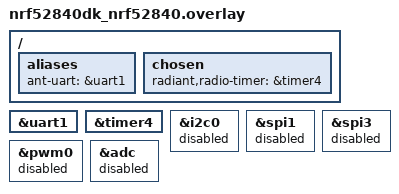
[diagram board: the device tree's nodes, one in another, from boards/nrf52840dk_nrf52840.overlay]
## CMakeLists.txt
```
# SPDX-License-Identifier: Apache-2.0

cmake_minimum_required(VERSION 3.20.0)

# The same ANT+ dongle as apps/dongle, plus Thread/Matter rebroadcast - see
# that app's own CMakeLists.txt header for why splitting the two apart,
# rather than a Kconfig variant of one, is the point.
#
# The sysbuild-cache reader and the RADIANT_BACKEND selection/assertion
# machinery are shared with every other RadiANT app (apps/dongle,
# apps/hrm_ble) rather than copy-pasted - see cmake/radiant_backend.cmake for
# the sysbuild mechanics this depends on. The ANT_RADIO axis (sdk_ant vs core
# vs stub) is the ANT-serial-dongle-specific half of the same idea, and lives
# in apps/common/ instead, for the reason that file's own header gives.
include("${CMAKE_CURRENT_SOURCE_DIR}/../../cmake/radiant_backend.cmake")
include("${CMAKE_CURRENT_SOURCE_DIR}/../common/ant_radio_backend.cmake")

# radiant is appended unconditionally, same reasoning as apps/dongle's own
# CMakeLists.txt: it is in this repository and always is, so CONFIG_RADIANT
# gates it rather than the module's presence gating anything.
#
# The default is "nrf", matching every other application in this repository.
# It used to be "null" on a cheap-compile-check argument; that argument is
# withdrawn, because the thing it protected - a bare `west build` that always
# configures - is worth less than never silently producing an inert radio.
#
# Note that "nrf" is the whole of the backend axis here. The P4 gate is NOT a
# RADIANT_BACKEND value: it is a separate Kconfig symbol,
# CONFIG_RADIANT_BACKEND_NRF_GATE_MPSL, which every fragment that turns on a
# second stack sets for itself (thread.conf, gate.conf, coex.conf, matter.conf).
# That is what satisfies RADIANT_BACKEND_NRF's `depends on !BT ||
# RADIANT_BACKEND_NRF_GATE_MPSL`, so this default is safe in the bare
# configuration - prj.conf alone enables neither BT nor OpenThread - and in
# every fragment combination the app actually ships.
#
# scripts/build_p4.ps1 still passes -DRADIANT_BACKEND=nrf explicitly and still
# reads .config back to prove it landed. Both remain right: an explicit flag
# and a read-back do not stop being worthwhile because the default now agrees
# with them.
radiant_select_backend("${CMAKE_CURRENT_SOURCE_DIR}/../../radiant" "nrf" RADIANT_BACKEND_CONF)
ant_select_radio("${CMAKE_CURRENT_SOURCE_DIR}" "" "${RADIANT_BACKEND_CONF}" ANT_RADIO_CONF)

# Write only on a change - see apps/dongle/CMakeLists.txt for the full
# rationale (CMAKE_CONFIGURE_DEPENDS churn on every configure otherwise).
set(ANT_RADIO_CONF_FILE "${CMAKE_CURRENT_BINARY_DIR}/ant_radio_backend.conf")
set(ANT_RADIO_CONF_EXISTING "")
if(EXISTS "${ANT_RADIO_CONF_FILE}")
  file(READ "${ANT_RADIO_CONF_FILE}" ANT_RADIO_CONF_EXISTING)
endif()
if(NOT ANT_RADIO_CONF_EXISTING STREQUAL ANT_RADIO_CONF)
  file(WRITE "${ANT_RADIO_CONF_FILE}" "# Generated by CMakeLists.txt from -DANT_RADIO. Do not edit; do not commit.\n${ANT_RADIO_CONF}")
endif()

find_package(Zephyr REQUIRED HINTS $ENV{ZEPHYR_BASE})
project(radiant_dongle_thread)

# See apps/common/ant_radio_backend.cmake's ant_assert_radio() - only
# relevant when ANT_RADIO chose radiant in the first place.
ant_assert_radio("radiant_dongle_thread")

target_sources(app PRIVATE src/main.c)

# ── apps/common: the antr_* seam, the serial bridge and its transports ─────
#
# One source list, added fresh into this application's own image - see that
# file's own header for why it is include()d rather than add_subdirectory()'d.
# CONFIG_ANT_DONGLE_TRANSPORT_* (set by the choice in Kconfig) and
# CONFIG_ANT_DONGLE_RADIO_*/CONFIG_RADIANT_ANTR_API (set above by
# ant_select_radio() and by apps/common/Kconfig.antr_api's default) together
# decide what actually compiles from it into this image.
include("${CMAKE_CURRENT_SOURCE_DIR}/../common/sources.cmake")

# ── The RadiANT bridge: the sample bus and everything on it ─────────────────
#
# docs/radiant-bridge.md sections 3-6 and 9. THE MODULE OWNS radiant/src/bridge/
# AND radiant/src/profiles/: CONFIG_RADIANT_BRIDGE (radiant/Kconfig) compiles
# both into the radiant library, adds both include paths and adds the linker
# fragment. This application lists none of those files - listing them as well
# is a duplicate-definition link failure, which is what 1d0d821 caused here.
# Only this application's own half, under src/, is added below.
#
# What decides which module code is LINKED is therefore the call graph, not a
# source list. The files with no sink (the bus, the binding table, the
# adapters, naming, the owed list, the self-channel policy, every profile
# codec) are dropped by the linker unless something here calls them. The three
# files that register a sink cannot be left to the linker, because a
# RADIANT_SINK_DEFINE() is kept whether or not anything calls into its file:
# radiant_rules.c and radiant_liveness.c follow CONFIG_RADIANT_BRIDGE_RULES and
# CONFIG_RADIANT_BRIDGE_LIVENESS, which this application's Kconfig defaults on,
# and radiant_matter.c follows CONFIG_RADIANT_BRIDGE_MATTER_MAP, which
# CONFIG_ANT_DONGLE_MATTER_MAP selects. Liveness lands with the bus, not after
# a sink: RADIANT_SAMPLE_STALE was defined and honoured since P6 with nothing
# producing it, and a sink written against a bus that never marks anything
# stale grows that assumption into itself.
#
# THE LINKER FRAGMENT IS NOT OPTIONAL, even though it is now the module's line
# rather than this file's. RADIANT_SINK_DEFINE() (radiant_bridge.h) uses
# STRUCT_SECTION_ITERABLE, which emits each sink into a section named after the
# struct type. Emitting into a section and having that section PLACED - with
# the _radiant_sink_list_start / _end symbols STRUCT_SECTION_FOREACH() walks
# between - are two different things, and radiant_sink has no in-tree linker
# fragment of its own the way shell commands and bt_conn_cb do. Without it the
# best case is an undefined reference at the final link; the worse case is that
# it links and STRUCT_SECTION_FOREACH() silently iterates ZERO sinks, which is
# not a compile error, not a link error, and looks from the console exactly
# like "no sensors in range". src/bridge_pump.c logs the count at boot for that
# reason: "bridge: 0 sinks" is the failure announcing itself.
#
# radiant_rd_adapter.c is compiled by the module and deliberately NOT CALLED
# here, so it is not linked. It is tested (radiant/tests builds it), but the
# running-dynamics adapter has no bench evidence behind it yet, and linking it
# would make an untested path look like a shipped one.
#
# radiant_matter.c is on ITS OWN Kconfig symbol (CONFIG_ANT_DONGLE_MATTER_MAP),
# not on CONFIG_CHIP. It contains no CHIP call at all: it is the section 8.1
# field-type -> cluster map plus a __weak radiant_matter_attr_write(), and it
# compiles identically with or without connectedhomeip in the workspace. Tying
# it to CONFIG_CHIP would have made a pure-C lookup table unbuildable on the
# nRF52840 Matterless escape hatch (docs/radiant-bridge.md section 11) for no
# reason, and Kconfig says why it defaults to n even here.
#
# The Matter plan's packages A, B and C - three more adapters and the page
# codecs behind them - follow CONFIG_ANT_DONGLE_PROFILES_EXTRA, which gates the
# CALLS in src/rx_tap.c and src/self_channels.c. NOT CONFIG_RADIANT_BRIDGE, AND
# THAT IS THE WHOLE POINT OF THE SYMBOL: docs/matter-bringup.md measured
# bridge.conf gaining 2 564 B of flash, 1 472 B of RAM and 22 defined symbols
# plus a changed radio schedule when they were not separate. See that symbol's
# help in Kconfig. Two things about what it links are load-bearing:
#
# 1. THE COMMON-PAGE PAIR IS NOT OPTIONAL AND IS NOT PER-PROFILE.
#    ANT+ Common Data Pages Rev 3.1 Table 4-1 keys pages 0x40-0x5D on the
#    channel's TRANSMISSION TYPE, not on the device type, so the common
#    decoder runs on every bound channel alongside whichever profile
#    adapter owns it - see src/rx_tap.c. Omitting it does not disable a
#    feature, it makes every weather-reporting sensor silent.
#
# 2. profile_power_decode.c, NOT profile_power.c. The latter is the
#    MASTER - page rotation, the ANT+ compat layer, RadiANT beacon
#    insertion - so it calls profile_sched.c and profile_compat.c, and
#    profile_compat.c reaches radiant_sec. Both are compiled by the module;
#    calling profile_power.c from here to obtain one decoder would pull the
#    entire transmit-side chain into an image whose whole job is to listen,
#    and would let a linker decision nobody reviewed make a receive-only
#    dongle capable of transmitting. See that file's header; the split exists
#    for this reason. `nm` on the ELF is the check: no profile_power_*
#    master symbol may appear.
if(CONFIG_RADIANT_BRIDGE)
  # The application half: the drain pump and the 1 Hz liveness clock.
  target_sources(app PRIVATE "${CMAKE_CURRENT_SOURCE_DIR}/src/bridge_pump.c")
  target_include_directories(app PRIVATE "${CMAKE_CURRENT_SOURCE_DIR}/src")
endif()

# ── The CHIP stack and the vendored Matter bridge core (package E3/E7) ──────
#
# EVERYTHING MATTER IS INSIDE THIS ONE `if`, and that is a requirement rather
# than tidiness. gate.conf, thread.conf, thread_sed.conf, coex.conf and
# bridge.conf carry the P3/P4 coexistence baselines in
# docs/radiant-bridge.md section 7.4, and those numbers describe the images
# they were taken on. CONFIG_CHIP is n in all five (matter_sysbuild.conf is
# named on the command line, never picked up automatically - see that file's
# header), so not one line below runs for them and their images are unchanged
# by construction rather than by care.
#
# WHY IT IS HERE AND NOT BEFORE find_package(Zephyr). The preamble at the top
# of this file - radiant_backend.cmake and ant_radio_backend.cmake - only
# generates .conf fragments and appends module paths; it creates no target and
# reads no Kconfig. Everything below needs both `app` to exist and
# CONFIG_* to be readable, so it belongs after project(). The two NCS
# applications that do this - nrf/applications/matter_bridge/CMakeLists.txt
# and nrf/samples/matter/template/CMakeLists.txt - are laid out exactly this
# way and this block follows them line for line.
#
# THE APPLICATION DOES NOT BECOME C++. Only the .cpp files listed below are,
# and enable-gnu-std.cmake only appends C++ flags. src/main.c and everything
# under apps/common stay C, and CONFIG_STD_CPP17 (matter.conf, with a long
# note on why it is not optional) applies to the C++ half alone.
if(CONFIG_CHIP)
  # -std=gnu++17 rather than -std=c++17 for the CHIP sources. Without it,
  # connectedhomeip does not compile - see matter.conf's CONFIG_STD_CPP17 note
  # for the 40-line error that looks like a broken toolchain and is not.
  include(${ZEPHYR_CONNECTEDHOMEIP_MODULE_DIR}/config/nrfconnect/app/enable-gnu-std.cmake)

  # NCS's Matter sample-common sources: board/led_widget, the task executor,
  # matter_init, the event handler and the code-driven cluster registry (plus
  # its cluster_init.ld linker fragment, which this file therefore does NOT
  # repeat). Every Matter sample and application in NCS includes this and the
  # bridge core expects the persistent-storage and binding pieces of it to be
  # present.
  #
  # board.cpp IS COMPILED AND DOES NOT DRIVE ANY LED HERE. Both its LED paths
  # are inside `#ifdef CONFIG_DK_LIBRARY` and this arm does not enable
  # DK_LIBRARY, so the collision matter.conf's CONFIG_NCS_SAMPLE_MATTER_LEDS=n
  # was written to prevent (NCS driving DK LEDs 0-3 against
  # apps/common/ant_heartbeat_led.c's led0) cannot happen twice over. The =n line
  # stays because it states the decision; this comment states the measurement.
  include(${ZEPHYR_NRF_MODULE_DIR}/samples/matter/common/cmake/source_common.cmake)

  # ncs_configure_data_model() and ncs_get_zap_parent_dir(), both of which read
  # CONFIG_NCS_SAMPLE_MATTER_ZAP_FILE_PATH - set in matter.conf to this
  # application's own src/matter/default_zap/bridge.zap.
  include(${ZEPHYR_NRF_MODULE_DIR}/samples/matter/common/cmake/data_model.cmake)
  include(${ZEPHYR_NRF_MODULE_DIR}/samples/matter/common/cmake/zap_helpers.cmake)
  ncs_get_zap_parent_dir(ZAP_PARENT_DIR)

  target_include_directories(app PRIVATE
    "${CMAKE_CURRENT_SOURCE_DIR}/src/matter"
    "${CMAKE_CURRENT_SOURCE_DIR}/src/matter/core"
    "${CMAKE_CURRENT_SOURCE_DIR}/src/matter/core/util"
    # zap-generated/ lands on the include path through its PARENT directory,
    # because the generated sources include it as <zap-generated/...>. This is
    # the line that makes the committed ZAP output the thing the build reads;
    # ncs_configure_data_model() adds the same directory to the separate
    # matter-data-model target.
    ${ZAP_PARENT_DIR}
  )

  target_sources(app PRIVATE
    # The vendored bridge core. src/matter/README.md records the source path,
    # the NCS version and everything that was left behind - the whole BLE
    # central provider first among it.
    "${CMAKE_CURRENT_SOURCE_DIR}/src/matter/core/bridge_manager.cpp"
    "${CMAKE_CURRENT_SOURCE_DIR}/src/matter/core/matter_bridged_device.cpp"
    "${CMAKE_CURRENT_SOURCE_DIR}/src/matter/core/bridge_storage_manager.cpp"
    "${CMAKE_CURRENT_SOURCE_DIR}/src/matter/core/bridged_device_data_provider.cpp"
    # NOT vendored, referenced in place, exactly as matter_bridge does:
    # BridgeManager::Init() calls Nrf::Matter::BindingHandler::Init() and
    # BridgeManager::HandleCommand() builds its BindingData. It is NCS's file
    # and there is no reason for this repository to own a copy.
    "${ZEPHYR_NRF_MODULE_DIR}/samples/matter/common/src/binding/binding_handler.cpp"
  )

  # ── Packages E4, E5 and E6: the ANT+ half, the device types and main() ────
  #
  # Everything here is THIS repository's, not vendored - src/matter/README.md's
  # provenance table covers core/ and default_zap/ and nothing below.
  #
  # ONE OF THESE FIVE FILES IS C, AND THAT IS DELIBERATE.
  # ant/ant_matter_sink.c carries the RADIANT_SINK_DEFINE() that gives the glue
  # a binding_changed callback and a view of RADIANT_SAMPLE_STALE. That macro is
  # STRUCT_SECTION_ITERABLE plus a designated initialiser; designated
  # initialisers are only a GNU extension in C++17 and the iterable-section
  # machinery wants an unmangled symbol in a section named after the struct.
  # Both happen to work under -std=gnu++17 and neither is guaranteed, so the
  # nine lines that need them are C. See that file's header.
  #
  # NESTED INSIDE CONFIG_RADIANT_BRIDGE, exactly like the trap-15 assertions
  # below and for the same mechanical reason: ant_bridge.cpp includes
  # radiant_matter.h and ant_matter_sink.c includes radiant_bridge.h, and
  # radiant/src/bridge only reaches the include path when the module sees
  # CONFIG_RADIANT_BRIDGE (src/bridge_app.h likewise comes from the block
  # further up). It is not a second opinion about
  # whether Matter is wanted - matter.conf sets both symbols and CONFIG_CHIP
  # without the sample bus would be a bridge with nothing to bridge.
  #
  # Note what is NOT the guard: CONFIG_ANT_DONGLE_MATTER, which is what main.c
  # tests. That symbol `depends on CHIP` and has no default, so a CHIP build
  # that left it unset compiles these files, links them, and finds nothing
  # calls ant_matter_start() - a dead sink and a --gc-sections discard. The
  # other order (guarding the sources and not the call) is the one that fails,
  # at link.
  if(CONFIG_RADIANT_BRIDGE)
    target_sources(app PRIVATE
      "${CMAKE_CURRENT_SOURCE_DIR}/src/matter/ant/ant_bridge.cpp"
      "${CMAKE_CURRENT_SOURCE_DIR}/src/matter/ant/ant_matter_sink.c"
      "${CMAKE_CURRENT_SOURCE_DIR}/src/matter/bridged_device_types/occupancy_sensor.cpp"
      "${CMAKE_CURRENT_SOURCE_DIR}/src/matter/bridged_device_types/measurement_sensor.cpp"
      # E6. It also carries the one LOG_MODULE_REGISTER(app) this image has:
      # every vendored core file and every NCS sample-common source does
      # LOG_MODULE_DECLARE(app), and upstream registers it in the main.cpp that
      # E3 deliberately did not vendor.
      "${CMAKE_CURRENT_SOURCE_DIR}/src/matter/matter_app.cpp"
      # Trap 15's static_assert. Same include-path reason as the four above;
      # not a statement that the assertion is optional.
      "${CMAKE_CURRENT_SOURCE_DIR}/src/matter/bridge_core_asserts.cpp")
  endif()

  # Compiles src/matter/default_zap/zap-generated/ into the matter-data-model
  # target, with BYPASS_IDL - so chip_zapgen never runs and the COMMITTED
  # directory is what the image contains. See src/matter/README.md; this is
  # trap 13 and it is the reason .zap, .matter and zap-generated/ were copied
  # across together and unmodified.
  ncs_configure_data_model()
endif()

# ADR 0018 Phase 1 bench BLE load (ble_load.conf). Never in a shipping image.
target_sources_ifdef(CONFIG_ANT_DONGLE_BLE_LOAD app PRIVATE
  "${CMAKE_CURRENT_SOURCE_DIR}/src/ble_load.c")

target_sources_ifdef(CONFIG_ANT_DONGLE_RX_TAP app PRIVATE
  "${CMAKE_CURRENT_SOURCE_DIR}/src/rx_tap.c")

# CONFIG_ANT_DONGLE_SELF_CHANNELS is an int, so target_sources_ifdef() (which
# tests for truthiness) would fire on 0 as well - Kconfig writes
# CONFIG_ANT_DONGLE_SELF_CHANNELS=0 rather than leaving it unset for an int
# symbol. Compare explicitly.
if(CONFIG_ANT_DONGLE_SELF_CHANNELS GREATER 0)
  # Its decisions are pure functions in radiant/src/bridge/radiant_self_policy.c,
  # where radiant/tests can reach them (this app's sources it cannot); the
  # module compiles that file under CONFIG_RADIANT_BRIDGE. See that header.
  target_sources(app PRIVATE "${CMAKE_CURRENT_SOURCE_DIR}/src/self_channels.c")
  # try_bind() once fell off its end and the built code returned a stale
  # register, rotating a just-bound channel away (review 2026-10-31, C3-1).
  # Per file, not app-wide: app-wide would reach vendored and zap C++.
  set_source_files_properties("${CMAKE_CURRENT_SOURCE_DIR}/src/self_channels.c"
    PROPERTIES COMPILE_OPTIONS "-Werror=return-type")
endif()

target_sources_ifdef(CONFIG_ANT_DONGLE_MQTT_SINK app PRIVATE
  "${CMAKE_CURRENT_SOURCE_DIR}/src/mqtt_sink.c")

# ── The hostless node's identity (compat-C6) ────────────────────────────────
#
# Same wiring as apps/dongle's own CMakeLists.txt - see that file's comment
# for the full rationale. Off by default here too: this application's epoch
# authority is still the PC behind it, same as the plain dongle.
if(CONFIG_RADIANT_NODE_IDENT)
  target_sources(app PRIVATE ../../radiant/src/node/node_ident.c)
  target_include_directories(app PRIVATE ../../radiant/src/node)
endif()
if(CONFIG_RADIANT_NODE_NVM_SETTINGS)
  target_sources(app PRIVATE ../../radiant/src/node/node_nvm_settings.c)
endif()
```

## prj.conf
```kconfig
# Board-specific settings live in boards/<board>.conf. The Thread/coexistence
# stack itself is opt-in through EXTRA_CONF_FILE (gate.conf, coex.conf,
# thread.conf, thread_sed.conf) rather than baked in here, so a plain
# `west build apps/dongle_thread` with no extra fragment is an ordinary
# ANT+-only dongle image - see scripts/build_p4.ps1 for how the bench arms
# turn the second stack on.

# The ANT stack settings - CONFIG_ANT, CONFIG_ANT_EVALUATION_KEY,
# CONFIG_ANT_TOTAL_CHANNELS_ALLOCATED and CONFIG_ANT_BURST_QUEUE_SIZE - are
# written by CMakeLists.txt into a generated fragment alongside the
# CONFIG_ANT_DONGLE_RADIO_* symbol naming the backend, same as apps/dongle.
# They name symbols that exist only when sdk-ant's Kconfig has been sourced,
# and it is CMake that decides whether that happens.

# Logging via RTT by default; a board's own boards/<board>.conf overrides
# this to a UART VCOM where RTT needs tooling the bench does not carry.
CONFIG_LOG=y
CONFIG_LOG_MODE_DEFERRED=y
CONFIG_USE_SEGGER_RTT=y
CONFIG_LOG_BACKEND_RTT=y
CONFIG_LOG_BACKEND_UART=n
CONFIG_SEGGER_RTT_MODE_NO_BLOCK_SKIP=y
CONFIG_LOG_BACKEND_RTT_MODE_DROP=y

# Heap and threads
CONFIG_HEAP_MEM_POOL_SIZE=4096
CONFIG_MAIN_STACK_SIZE=2048
CONFIG_RESET_ON_FATAL_ERROR=y
CONFIG_REBOOT=y

CONFIG_CONSOLE=n
CONFIG_UART_CONSOLE=n
CONFIG_SHELL=n

CONFIG_ANT_DONGLE_BCD_DEVICE=0x0100

# The boot sequence itself is apps/common/ant_dongle_main.c, shared with
# apps/dongle. This is the one line of it that differs between the two
# applications; src/main.c's override of the weak post-radio hook is the other
# difference, and it is code rather than configuration.
CONFIG_ANT_DONGLE_MAIN_BANNER="ANT+ USB Dongle + Thread"

# Ring buffer for USB RX data
CONFIG_RING_BUFFER=y

# GPIO for onboard LED activity signal
CONFIG_GPIO=y

# The boot reset cause - see apps/dongle/prj.conf.
CONFIG_HWINFO=y
```

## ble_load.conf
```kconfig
# SPDX-License-Identifier: Apache-2.0
#
# Bench only (ADR 0018 Phase 1): coex.conf plus an advertiser that actually
# advertises (src/ble_load.c), so MPSL has a second stack with events on the
# schedule. Use instead of gate.conf:
#
#   "-DEXTRA_CONF_FILE=coex.conf;ble_load.conf;phase_diag.conf;d2_stats.conf"
#
# Never in a shipping image.
CONFIG_ANT_DONGLE_BLE_LOAD=y
CONFIG_ANT_DONGLE_BLE_LOAD_INTERVAL_MS=1000
```

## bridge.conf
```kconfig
# SPDX-License-Identifier: Apache-2.0
#
# The RadiANT bridge, as a build: ANT+ in, MQTT over Thread out.
#
#   west ... -- "-DANT_RADIO=core" "-DRADIANT_BACKEND=nrf" \
#               "-DEXTRA_CONF_FILE=thread.conf;bridge.conf"
#
# ---------------------------------------------------------------------------
# THIS IS A SEPARATE FRAGMENT ON PURPOSE. DO NOT FOLD IT INTO thread.conf.
# ---------------------------------------------------------------------------
#
# CONFIG_NET_TCP is deliberately absent from thread.conf, which says why in its
# own words: flash the gate image does not need, plus air time the gate would
# then have to account for. docs/radiant-bridge.md section 7.4's coexistence
# numbers - the ones recorded in 7.4.2 as a PASS - were taken on a TCP-FREE
# IMAGE. An image with a TCP stack, a broker connection and a keepalive thread
# in it is a different image, and quoting 7.4's numbers against it would be
# quoting a measurement of something else.
#
# So: the gate arms (gate.conf, thread.conf, thread_sed.conf) stay TCP-free,
# this fragment layers on top of thread.conf for a bridge build, and a
# coexistence figure taken with this fragment on is its own measurement with
# its own row.

# ── The bus ────────────────────────────────────────────────────────────────
#
# Note what this brings with it: the linker fragment
# radiant/src/bridge/radiant_bridge_sections.ld, through
# zephyr_linker_sources() in radiant/CMakeLists.txt, along with the module's
# bridge and profile sources. Watch for "bridge: N sinks" in the
# boot log; N of 0 means every sink in the image is dead code and nothing
# downstream can work.
CONFIG_RADIANT_BRIDGE=y
CONFIG_ANT_DONGLE_RX_TAP=y

# ── Self-driving channels and the pairing window ───────────────────────────
#
# Two channels, taken from the top of the ANT allocation downward so a host
# library allocating from 0 upward collides last. Acquiring is not binding: a
# press of sw0 opens a 60 s window, and outside it an unbound device's
# broadcasts are dropped (section 10.1 rule 1, and section 5 - binding is
# explicit opt-in, never promiscuous).
CONFIG_ANT_DONGLE_SELF_CHANNELS=2
CONFIG_ANT_DONGLE_PAIRING_WINDOW_S=60

# ── MQTT ───────────────────────────────────────────────────────────────────
#
# TCP is the whole reason this fragment exists. NET_SOCKETS, NET_IPV6 and the
# OpenThread L2 come from thread.conf, which this is layered on top of.
CONFIG_NET_TCP=y
CONFIG_MQTT_LIB=y
CONFIG_MQTT_LIB_TLS=n

CONFIG_ANT_DONGLE_MQTT_SINK=y

# A PLACEHOLDER, and it is certainly not your broker. Numeric IPv6 only:
# section 9.0a's DNS-SD discovery is deferred (it rests on two things nobody
# has verified on real hardware), so there is no resolver call in this build
# and a hostname here is an error rather than an unimplemented feature.
CONFIG_ANT_DONGLE_MQTT_BROKER="fd11:22::1"
CONFIG_ANT_DONGLE_MQTT_PORT=1883
CONFIG_ANT_DONGLE_MQTT_BRIDGE_ID="radiant0"

# CONFIG_NET_CONFIG_NEED_IPV6 IS DELIBERATELY ABSENT HERE TOO, and the reason
# is thread.conf's, unchanged: it blocks net_config_init() until the interface
# has an IPv6 address, before main(), for up to 30 s - measured at 31.04 s on
# an unattached MTD on this bench, reproducible to the tenth, and read as a
# hung board by a human and by ant_verify.py in the same session.
#
# src/mqtt_sink.c connects on its FIRST PUBLISH and never at boot. A connect
# that fails is retried on the next sample rather than being fatal.
#
# ONE CORRECTION TO thread.conf's WORDING, FOUND BY READING THIS BUILD'S OWN
# .config RATHER THAN THE FRAGMENTS. thread.conf says NET_CONFIG_NEED_IPV6 is
# "deliberately absent"; it is absent from that FILE, but it defaults to y once
# CONFIG_NET_CONFIG_SETTINGS and CONFIG_NET_IPV6 are both on, and this build's
# generated .config reads CONFIG_NET_CONFIG_NEED_IPV6=y. What actually prevents
# the 31 s stall is the line beside it - CONFIG_NET_CONFIG_INIT_TIMEOUT=0,
# which makes the wait return immediately.
#
# So the timeout is restated HERE rather than inherited, because it is the line
# that is load-bearing and a fragment layered on top of a different base must
# not lose it. Verified in build/p2_bridge/dongle_thread/zephyr/.config:
# NEED_IPV6=y, INIT_TIMEOUT=0.
CONFIG_NET_CONFIG_INIT_TIMEOUT=0

# Buffers. The bridge adds a TCP connection, a 512 B MQTT tx buffer, a 256 B rx
# buffer and two threads to the OpenThread build's existing demand; thread.conf
# sizes the heap for OpenThread alone, so this raises it rather than discovering
# the shortfall as intermittent send failures that look like contention loss.
CONFIG_HEAP_MEM_POOL_SIZE=49152
CONFIG_NET_PKT_RX_COUNT=16
CONFIG_NET_PKT_TX_COUNT=16
CONFIG_NET_BUF_RX_COUNT=32
CONFIG_NET_BUF_TX_COUNT=32

# ── Reboot on a fatal error: the SHIPPING setting ──────────────────────────
#
# thread.conf sets this n, as a bench setting for the gate arms: a halted board
# keeps its fault dump on the console. This build is the one a user leaves
# running, and a bridge that halts on a transient fault publishes nothing until
# someone power-cycles it, where one that reboots is back within seconds. So
# this fragment overrides thread.conf here. It covers the MPSL assert too:
# radiant_radio_nrf_gate_mpsl.c's mpsl_assert_handle() reboots under this
# symbol and halts without it. Nothing survives the reboot - no crash record,
# since diag_flash_log.c cannot link beside this setting - so on the bench the
# dump on the console is all there is; build with thread.conf alone to get a
# board that stays halted on it.
CONFIG_RESET_ON_FATAL_ERROR=y
```

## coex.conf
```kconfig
# SPDX-License-Identifier: Apache-2.0
#
# The multiprotocol plan's P3 coexistence gate, as a build.
#
# SCOPE, SINCE THE LOAD GENERATOR WAS RETIRED: P3/P4 concluded and
# ble_coex_load.c was deleted with it, so this fragment no longer advertises
# anything. What it still buys is the build-time half - that CONFIG_BT=y beside
# the gate links, and that the backend does not fall to null (the second trap
# below). It is NOT a runtime coexistence measurement any more, and a CI row
# building it proves nothing about air behaviour. Restoring the adversarial
# advertiser means restoring ble_coex_load.c from git history.
#
#   west ... -- "-DANT_RADIO=core" "-DRADIANT_BACKEND=nrf" \
#               "-DEXTRA_CONF_FILE=coex.conf"
#
# -DANT_RADIO=core IS NOT OPTIONAL AND IS NOT THE DEFAULT. The root build
# defaults to the sdk-ant radio, which leaves CONFIG_RADIANT=n - and then
# every RADIANT_* line below is dropped with an "unsatisfied dependencies:
# RADIANT (=n)" warning. Leaving it out here fails loudly only by accident
# (sdk-ant then fails to link for the wrong float ABI); on a board where it
# links, it would silently measure the sdk-ant stack instead of this one.
#
# This is the CONTENDED half of an A/B. The other half is the same image without
# this fragment: gate on, no second stack. Read both or neither - the question
# the gate answers is a difference between two images, never a property of one.
#
# WHY EVERY LINE IS HERE, because three of the four are silent-fallback traps
# this project has now paid for more than once:
#
#   - CONFIG_BT=y ALONE IS NOT A SECOND STACK. It links the SoftDevice
#     Controller in and leaves it asleep, asking MPSL for no air whatsoever.
#     Measured, and it produced a sweep-rate ratio of exactly 1.000 between
#     "BLE off" and "BLE on" - a gate that cannot fail.
#   - CONFIG_BT=y also breaks the `!BT` half of RADIANT_BACKEND_NRF's
#     `depends on !BT || RADIANT_BACKEND_NRF_GATE_MPSL`, so without the
#     gate line below the whole radio backend silently becomes
#     RADIANT_BACKEND_NULL - an image that enumerates, answers the host,
#     and puts nothing on the air. That is not a bad measurement, it is a
#     measurement of nothing, and it reports EXIT=0.
#   - The gate itself is `select MPSL`, so nothing else needs turning on. It was
#     `depends on MPSL` once, which meant asking for the arbitrated build
#     without a second stack quietly compiled the DIRECT backend - i.e. the A of
#     this very A/B measured the wrong thing.
#
# ALWAYS CHECK THE GENERATED .config, NOT THE BUILD LOG. Every trap above ends
# in a warning among a hundred others and an exit code of 0:
#
#   Select-String build\<dir>\<app>\zephyr\.config `
#       -Pattern "^CONFIG_RADIANT_BACKEND_"
#
# EXEMPTION FROM THE W2 BLE POLICY (apps/hrm_ble/Kconfig,
# apps/treadmill/Kconfig): those two applications now redeclare
# BT_PERIPHERAL_PREF_MIN_INT/MAX_INT/LATENCY/TIMEOUT to 800/800/0/400 and
# fix le_param_req to enforce it, because THEY are the ANT+ side that needs
# BLE shaped down to 1 s. This file is the opposite instrument: it is the
# bench advertiser the gate is measured AGAINST, and its whole job is to be
# the adversarial neighbour those two applications defend against - at a
# deliberately-adversarial 100 ms advertising rate. Applying the 1 s policy
# here would tune the load down and understate every number the coexistence
# gate produces. Deliberately left off. (Moot while the load generator is
# retired - see SCOPE above - but the reasoning stands if it is restored.)

CONFIG_BT=y
CONFIG_BT_PERIPHERAL=y
CONFIG_BT_DEVICE_NAME="RadiANT Coex Load"

# Named rather than inherited. It is the default controller on a Nordic board,
# so this line changes nothing today - and it is the one fact that makes the
# plan's finding 1 true: the SoftDevice Controller is another MPSL user holding
# priority levels above anything an application timeslot request may ask for. A
# build that had silently fallen back to the Zephyr controller would be
# measuring a different arbitration, and every number would be optimistic.
#
# CONFIG_BT_CTLR is NOT a symbol to set - it is selected by the controller
# choice, and assigning it in v3.4.0 is a Kconfig warning that fails the build.
CONFIG_BT_LL_SOFTDEVICE=y

# The arbiter. See the second trap above: with CONFIG_BT=y and without this,
# the radio backend is silently the null one.
CONFIG_RADIANT_BACKEND_NRF_GATE_MPSL=y
# ADR 0018 (d2): one more for the gate's second session (RADIANT_GATE_MPSL_D2).
CONFIG_MPSL_TIMESLOT_SESSION_COUNT=2
```

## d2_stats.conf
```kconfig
# SPDX-License-Identifier: Apache-2.0
#
# Bench only: the MPSL gate's counters every 5 s on the log console (GATESTAT).
# Add beside gate.conf, thread.conf or coex.conf. Never in a shipping image.
CONFIG_RADIANT_GATE_MPSL_STATS_LOG=y
```

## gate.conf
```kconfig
# SPDX-License-Identifier: Apache-2.0
#
# The A of the coexistence A/B: the arbiter, with NO second stack.
#
#   west ... -- "-DANT_RADIO=core" "-DRADIANT_BACKEND=nrf" \
#               "-DEXTRA_CONF_FILE=gate.conf"
#
# The B is coex.conf, which is this plus a SoftDevice Controller that actually
# advertises. Read the two together; a number from either alone says nothing,
# because the question is what the other stack's demand costs us and that is a
# difference between two images.
#
# WHY THIS FILE EXISTS AT ALL, rather than "just leave coex.conf off". Turning
# on the gate is one line, and getting it wrong is silent both ways:
#
#   - RADIANT_BACKEND_NRF_GATE_MPSL was once `depends on MPSL` rather than
#     `select MPSL`, and nothing else in this tree enables MPSL. So asking for
#     the arbitrated build without a second stack - i.e. THIS measurement -
#     quietly compiled the DIRECT backend, and the A of the A/B measured the
#     thing the A/B was trying to isolate. It is `select` now; this fragment
#     names it anyway, so the intent survives another refactor of that line.
#   - A build with neither this nor coex.conf is the DIRECT backend, which is a
#     legitimate third measurement (the floor) and NOT the A. Three builds,
#     three fragments' worth of intent: direct = neither file, arbiter-only =
#     this file, contended = coex.conf.
#
# CHECK THE GENERATED .config, NOT THE BUILD LOG:
#
#   Select-String build\<dir>\<app>\zephyr\.config -Pattern "^CONFIG_RADIANT_BACKEND_"
#
# Expect BACKEND_NRF=y AND BACKEND_NRF_GATE_MPSL=y. BACKEND_NULL=y here is the
# failure that reports EXIT=0 and puts nothing on the air.

CONFIG_RADIANT_BACKEND_NRF_GATE_MPSL=y
# ADR 0018 (d2): one more for the gate's second session (RADIANT_GATE_MPSL_D2).
CONFIG_MPSL_TIMESLOT_SESSION_COUNT=2
```

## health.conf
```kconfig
# SPDX-License-Identifier: Apache-2.0
#
# The 0xF6 health counters on the bridge image, for a bench that wants the
# reading. Off by default, same as apps/dongle/health.conf. On an MPSL build
# this brings in CONFIG_RADIANT_SEARCH_COVERAGE, so the reply is 32 bytes and
# carries sets_advanced_uncovered at [30..31]; see tools/ant_health.py.

CONFIG_ANT_DONGLE_HEALTH_COUNTERS=y
```

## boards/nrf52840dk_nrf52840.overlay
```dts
/*
 * nRF52840 DK - the "does Matter fit on an nRF52840" arm.
 *
 * Written for docs/matter-bringup.md. BUILD-ONLY: there is no nRF52840 DK on
 * this bench (the attached nRF52840 devices are a dongle and a Feather), so
 * nothing here has been exercised on hardware. The pin choices below are
 * whatever the board's own DTS already routes.
 *
 * uart0 is the J-Link OB VCOM and carries the console/log. uart1 is the
 * "arduino_serial" header UART - already pinned by the board DTS - and is what
 * the ANT byte stream goes out of, so logs and ANT do not interleave. On a DK
 * that means a second USB-serial adapter on P1.01/P1.02; on a real product
 * this would be the USB device peripheral instead.
 */

/ {
	aliases {
		ant-uart = &uart1;
	};

	chosen {
		/*
		 * The TIMER radiant's nrf backend owns outright. Five CC
		 * channels are required (t_sync capture, RX start, window
		 * close, software now-capture, TX start), which on nRF52 means
		 * TIMER3 or TIMER4 - TIMER0/1/2 have four. TIMER0 is also
		 * MPSL's on this family, so it could not be used here anyway.
		 *
		 * Naming it in devicetree rather than in the source is what
		 * makes a second user a devicetree conflict instead of two
		 * drivers reprogramming each other's prescaler.
		 */
		radiant,radio-timer = &timer4;
	};
};

&uart1 {
	status = "okay";
};

&timer4 {
	status = "okay";
};

/* Peripherals this image has no use for. Off so nothing in the DK's default
 * DTS quietly costs flash, RAM or current in a budget measurement. */
&i2c0 {
	status = "disabled";
};

&spi1 {
	status = "disabled";
};

&spi3 {
	status = "disabled";
};

&pwm0 {
	status = "disabled";
};

&adc {
	status = "disabled";
};
```

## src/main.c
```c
/* SPDX-License-Identifier: Apache-2.0 */

/*
 * ANT+ USB Dongle + Thread — main entry point.
 *
 * The boot sequence is apps/common/ant_dongle_main.c, byte-for-byte the same
 * one apps/dongle boots through; see apps/common/ant_dongle_main.h. What makes
 * this application different is the second wireless stack, and the whole of
 * that difference is the hook below.
 */

#include <zephyr/kernel.h>
#include <zephyr/logging/log.h>

#include "ant_dongle_main.h"

#if defined(CONFIG_ANT_DONGLE_MATTER)
/* src/matter is on this target's include path only inside CMakeLists.txt's
 * `if(CONFIG_CHIP)` block, which is exactly the condition
 * CONFIG_ANT_DONGLE_MATTER `depends on`. */
#include "ant/ant_matter.h"
#endif

LOG_MODULE_REGISTER(ant_dongle_thread, LOG_LEVEL_INF);

/*
 * Overrides the weak default in apps/common/ant_dongle_main.c. Runs after
 * antr_init() has succeeded and before the transport comes up.
 *
 * AFTER antr_init() is the whole reason the hook is at that point rather than
 * in main(): the radio backend holds an explicit HFXO request that is
 * load-bearing - without it the 1 MHz timebase runs 0.42 % fast on the
 * internal RC between timeslots, invisible in any counter.
 *
 * Failures here are logged, not fatal: ANT+ with no second stack beats
 * refusing to boot.
 *
 * The LOG_INF lines are not decoration. A weak override that failed to take
 * (a signature typo is the classic way) is otherwise completely silent, since
 * the default does nothing and boots fine; these lines are what proves on the
 * console that this file, and not the default, is what ran.
 */
void ant_dongle_post_radio_init(void)
{
#if defined(CONFIG_ANT_DONGLE_MATTER)
	/*
	 * Package E6. THIS RETURNS IMMEDIATELY, AND THAT IS A REQUIREMENT
	 * RATHER THAN AN OPTIMISATION. This hook runs before
	 * usb_ant_class_init(), so anything that blocks here delays USB
	 * enumeration - and a dongle that has not enumerated is a dongle that
	 * looks broken. thread.conf:60-75 records what that cost the last time
	 * (31.04 s in net_config_init(), read as a hung board by a human and by
	 * ant_verify.py in the same session).
	 *
	 * ant_matter_start() therefore only creates a thread;
	 * Nrf::Matter::PrepareServer(), the explicitly-blocking StartServer()
	 * and the application task loop are all on the far side of it. See
	 * src/matter/matter_app.cpp.
	 */
	LOG_INF("starting Matter application task");
	if (ant_matter_start() != 0) {
		LOG_ERR("Matter application task not started - this image will "
			"bridge nothing to Thread");
	}
#endif
}

int main(void)
{
	return ant_dongle_main_run();
}
```

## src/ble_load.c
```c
/* SPDX-License-Identifier: Apache-2.0 */
/*
 * ble_load.c - BENCH ONLY (ADR 0018 Phase 1). A connectable BLE advertiser
 * whose only job is to want the radio, so the MPSL gate's held grant can be
 * measured beside a second stack with events on the schedule. Started from a
 * SYS_INIT after a delay; touches nothing else. Replaces the P3/P4
 * ble_coex_load.c retired in fc04371. Never in a shipping image.
 */

#include <zephyr/bluetooth/bluetooth.h>
#include <zephyr/init.h>
#include <zephyr/kernel.h>
#include <zephyr/logging/log.h>

LOG_MODULE_REGISTER(ble_load, LOG_LEVEL_INF);

#define ADV_UNITS ((uint16_t)((CONFIG_ANT_DONGLE_BLE_LOAD_INTERVAL_MS * 1000) / 625))

static const struct bt_data adv_data[] = {
	BT_DATA_BYTES(BT_DATA_FLAGS, (BT_LE_AD_GENERAL | BT_LE_AD_NO_BREDR)),
};

static void start_fn(struct k_work *w)
{
	static const struct bt_le_adv_param param =
		BT_LE_ADV_PARAM_INIT(BT_LE_ADV_OPT_CONN, ADV_UNITS, ADV_UNITS, NULL);
	int rc;

	ARG_UNUSED(w);
	rc = bt_enable(NULL);
	if (rc != 0 && rc != -EALREADY) {
		LOG_ERR("BLE load: bt_enable %d", rc);
		return;
	}
	rc = bt_le_adv_start(&param, adv_data, ARRAY_SIZE(adv_data), NULL, 0);
	LOG_INF("BLE load: advertising every %d ms (rc %d)",
		CONFIG_ANT_DONGLE_BLE_LOAD_INTERVAL_MS, rc);
}

static K_WORK_DELAYABLE_DEFINE(start_work, start_fn);

static int ble_load_init(void)
{
	(void)k_work_schedule(&start_work, K_SECONDS(3));
	return 0;
}

SYS_INIT(ble_load_init, APPLICATION, 99);
```

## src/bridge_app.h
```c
/* SPDX-License-Identifier: Apache-2.0 */
/*
 * bridge_app.h - the application half of the RadiANT sample bus.
 *
 * radiant/src/bridge/ is the bus, the binding table, the rule evaluator and
 * the liveness table, and it reaches no radiant header and no antr_* header at
 * all - that is a property radiant/tests/CMakeLists.txt states as the reason
 * those files are compiled where they are. Everything in THIS directory is the
 * other side of that line: it is allowed to know about ANT channels, about
 * antr_*, about sockets and about buttons.
 *
 * Four files sit behind it:
 *   bridge_pump.c    - the drain thread and the 1 Hz liveness tick. Nothing
 *                      called radiant_bridge_drain() anywhere in the tree
 *                      before this file existed.
 *   rx_tap.c         - the ingest point: ANT broadcasts -> struct radiant_sample.
 *   self_channels.c  - wildcard slave channels and the pairing window.
 *   mqtt_sink.c      - one RADIANT_SINK_DEFINE onto an MQTT broker.
 */

#ifndef BRIDGE_APP_H_
#define BRIDGE_APP_H_

#include <stdbool.h>
#include <stdint.h>

#ifdef __cplusplus
extern "C" {
#endif

/*
 * THE ONE CLOCK. Every t_us on the bus and every now_us handed to
 * radiant_liveness_tick() comes from here, and if those two ever came from
 * different clocks the liveness table would either expire everything at once
 * or nothing ever - neither of which announces itself. One function, so there
 * is one place to be wrong.
 *
 * k_uptime_ticks() rather than k_uptime_get(): the tick counter is the
 * finest-grained monotonic source Zephyr offers portably, and converting once
 * here keeps the conversion out of the RX path's arithmetic.
 */
uint64_t ant_bridge_now_us(void);

/*
 * The channel -> binding map the RX tap consults. This is where
 * docs/radiant-bridge.md section 10.1 rule 1 ("no promiscuous ingest, ever")
 * is enforced in code rather than in prose: a broadcast arriving on a channel
 * with no entry here is DROPPED, whatever it contains. Binding is the act of
 * adding an entry, and only self_channels.c's pairing window does that.
 *
 * Returns 0, or -EINVAL for a channel outside the allocation.
 */
int  ant_bridge_channel_bind(uint8_t channel, uint32_t source);
void ant_bridge_channel_unbind(uint8_t channel);

/* RADIANT_BINDING_NONE if the channel carries no binding. */
uint32_t ant_bridge_channel_source(uint8_t channel);

/* How many broadcasts the tap has dropped for want of a binding. Exposed
 * because "the bridge is silent" and "the bridge is dropping everything on
 * purpose" look identical from outside, and this is the number that tells
 * them apart. */
uint32_t ant_bridge_unbound_drops(void);

/*
 * Open the pairing window (CONFIG_ANT_DONGLE_PAIRING_WINDOW_S seconds) as
 * though the button had been pressed. Exists so that a shell command or a
 * future host message has one entry point rather than reaching into
 * self_channels.c's state; the button is not the only legitimate way for a
 * user to say "yes, this one", it is only the one a bare DK has.
 *
 * Compiled only when CONFIG_ANT_DONGLE_SELF_CHANNELS > 0.
 */
void self_channels_open_pairing_window(void);

#ifdef __cplusplus
}
#endif

#endif /* BRIDGE_APP_H_ */
```
